# ESP32-S3 register map
Vendor: ESPRESSIF SYSTEMS (SHANGHAI) CO., LTD.; Series: ESP32 S-Series; File version: 22
CPU: Xtensa LX7 r0p0, little endian, no MPU, FPU, 0 interrupt priority bits
Address unit: 32 bits
Registers are 32-bit, read-write, reset 0x0 unless marked. A register's access mark holds for its fields unless they carry their own. Offsets are from the block's base; [hi:lo] are bit positions; {n}, {i} and the like mark numbered series.

## SENSITIVE (part 1 of 2) — SENSITIVE Peripheral
Base 0x600C1000
0x00 CACHE_DATAARRAY_CONNECT_0 — Cache data array configuration register 0.
  [0] CACHE_DATAARRAY_CONNECT_LOCK — Set 1 to lock cache data array registers.
0x04 CACHE_DATAARRAY_CONNECT_1 reset 0xFF — Cache data array configuration register 1.
  [7:0] CACHE_DATAARRAY_CONNECT_FLATTEN — Cache data array connection configuration.
0x08 APB_PERIPHERAL_ACCESS_0 — APB peripheral configuration register 0.
  [0] APB_PERIPHERAL_ACCESS_LOCK — Set 1 to lock APB peripheral Configuration Register.
0x0C APB_PERIPHERAL_ACCESS_1 reset 0x1 — APB peripheral configuration register 1.
  [0] APB_PERIPHERAL_ACCESS_SPLIT_BURST — Set 1 to support split function for AHB access to APB peripherals.
0x10 INTERNAL_SRAM_USAGE_0 — Internal SRAM configuration register 0.
  [0] INTERNAL_SRAM_USAGE_LOCK — Set 1 to lock internal SRAM Configuration Register.
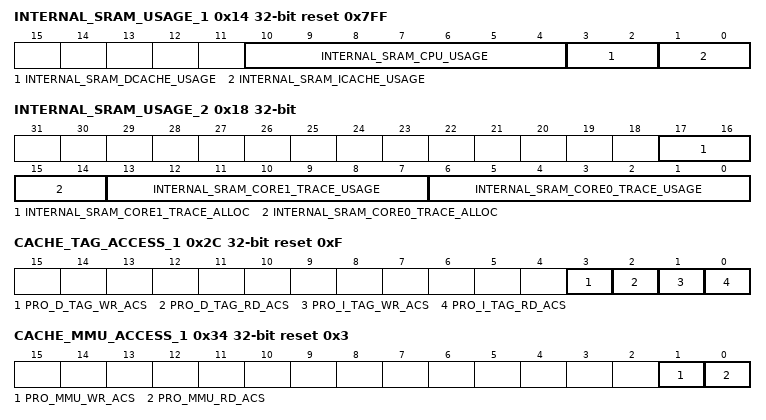
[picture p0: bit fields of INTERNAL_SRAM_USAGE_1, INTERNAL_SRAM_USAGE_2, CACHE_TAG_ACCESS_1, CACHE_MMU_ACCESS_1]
0x14 INTERNAL_SRAM_USAGE_1 reset 0x7FF — Internal SRAM configuration register 1.
  [10:4] INTERNAL_SRAM_CPU_USAGE — Set 1 to someone bit means corresponding internal SRAM level can be accessed by cpu.
  [3:2] INTERNAL_SRAM_DCACHE_USAGE — Set 1 to someone bit means corresponding internal SRAM level can be accessed by dcache.
  [1:0] INTERNAL_SRAM_ICACHE_USAGE — Set 1 to someone bit means corresponding internal SRAM level can be accessed by icache.
0x18 INTERNAL_SRAM_USAGE_2 — Internal SRAM configuration register 2.
  [17:16] INTERNAL_SRAM_CORE1_TRACE_ALLOC — Which internal SRAM bank (16KB) of 64KB can be accessed by core1 trace bus.
  [15:14] INTERNAL_SRAM_CORE0_TRACE_ALLOC — Which internal SRAM bank (16KB) of 64KB can be accessed by core0 trace bus.
  [13:7] INTERNAL_SRAM_CORE1_TRACE_USAGE — Set 1 to someone bit means corresponding internal SRAM level can be accessed by core1 trace bus.
  [6:0] INTERNAL_SRAM_CORE0_TRACE_USAGE — Set 1 to someone bit means corresponding internal SRAM level can be accessed by core0 trace bus.
0x1C INTERNAL_SRAM_USAGE_3 — Internal SRAM configuration register 3.
  [3:0] INTERNAL_SRAM_MAC_DUMP_USAGE — Set 1 to someone bit means corresponding internal SRAM level can be accessed by mac dump.
0x20 INTERNAL_SRAM_USAGE_4 — Internal SRAM configuration register 4.
  [6:0] INTERNAL_SRAM_LOG_USAGE — Set 1 to someone bit means corresponding internal SRAM level can be accessed by log bus.
0x24 RETENTION_DISABLE — Retention configuration register.
  [0] RETENTION_DISABLE — Set 1 to disable retention function and lock disable state.
0x28 CACHE_TAG_ACCESS_0 — Cache tag configuration register 0.
  [0] CACHE_TAG_ACCESS_LOCK — Set 1 to lock cache tag Configuration Register.
0x2C CACHE_TAG_ACCESS_1 reset 0xF — Cache tag configuration register 1.
  [3] PRO_D_TAG_WR_ACS — Set 1 to enable Dcache wrtie access tag memory.
  [2] PRO_D_TAG_RD_ACS — Set 1 to enable Dcache read access tag memory.
  [1] PRO_I_TAG_WR_ACS — Set 1 to enable Icache wrtie access tag memory.
  [0] PRO_I_TAG_RD_ACS — Set 1 to enable Icache read access tag memory.
0x30 CACHE_MMU_ACCESS_0 — Cache MMU configuration register 0.
  [0] CACHE_MMU_ACCESS_LOCK — Set 1 to lock cache MMU registers.
0x34 CACHE_MMU_ACCESS_1 reset 0x3 — Cache MMU configuration register 1.
  [1] PRO_MMU_WR_ACS — Set 1 to enable write access MMU memory.
  [0] PRO_MMU_RD_ACS — Set 1 to enable read access MMU memory.
0x38 DMA_APBPERI_SPI2_PMS_CONSTRAIN_0 — spi2 dma permission configuration register 0.
  [0] DMA_APBPERI_SPI2_PMS_CONSTRAIN_LOCK — Set 1 to lock spi2 dma permission Configuration Register.
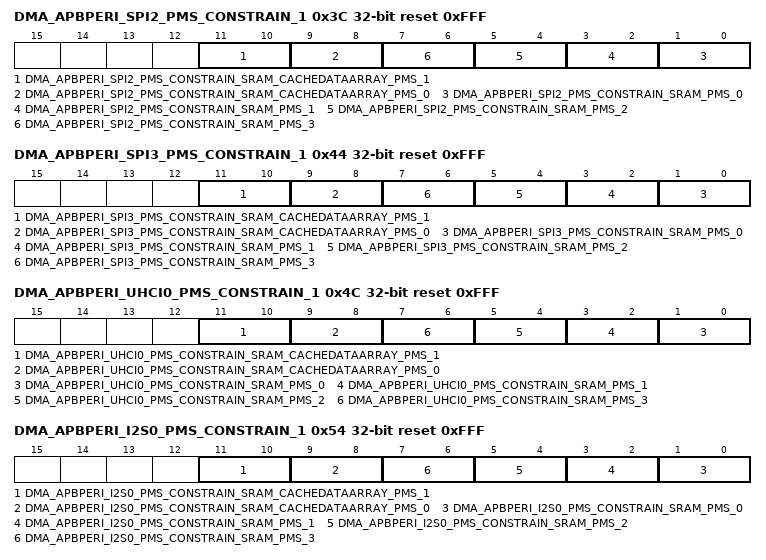
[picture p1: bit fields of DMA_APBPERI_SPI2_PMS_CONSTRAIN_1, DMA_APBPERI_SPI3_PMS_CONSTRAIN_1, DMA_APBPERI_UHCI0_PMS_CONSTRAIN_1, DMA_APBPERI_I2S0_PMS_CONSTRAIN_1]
0x3C DMA_APBPERI_SPI2_PMS_CONSTRAIN_1 reset 0xFFF — spi2 dma permission configuration register 1.
  [11:10] DMA_APBPERI_SPI2_PMS_CONSTRAIN_SRAM_CACHEDATAARRAY_PMS_1 — spi2's permission(store,load) in dcache data sram block1
  [9:8] DMA_APBPERI_SPI2_PMS_CONSTRAIN_SRAM_CACHEDATAARRAY_PMS_0 — spi2's permission(store,load) in dcache data sram block0
  [2n+1:2n] DMA_APBPERI_SPI2_PMS_CONSTRAIN_SRAM_PMS_{n} (n=0..3) — spi2's permission(store,load) in data region{n} of SRAM
0x40 DMA_APBPERI_SPI3_PMS_CONSTRAIN_0 — spi3 dma permission configuration register 0.
  [0] DMA_APBPERI_SPI3_PMS_CONSTRAIN_LOCK — Set 1 to lock spi3 dma permission Configuration Register.
0x44 DMA_APBPERI_SPI3_PMS_CONSTRAIN_1 reset 0xFFF — spi3 dma permission configuration register 1.
  [11:10] DMA_APBPERI_SPI3_PMS_CONSTRAIN_SRAM_CACHEDATAARRAY_PMS_1 — spi3's permission(store,load) in dcache data sram block1
  [9:8] DMA_APBPERI_SPI3_PMS_CONSTRAIN_SRAM_CACHEDATAARRAY_PMS_0 — spi3's permission(store,load) in dcache data sram block0
  [2n+1:2n] DMA_APBPERI_SPI3_PMS_CONSTRAIN_SRAM_PMS_{n} (n=0..3) — spi3's permission(store,load) in data region{n} of SRAM
0x48 DMA_APBPERI_UHCI0_PMS_CONSTRAIN_0 — uhci0 dma permission configuration register 0.
  [0] DMA_APBPERI_UHCI0_PMS_CONSTRAIN_LOCK — Set 1 to lock uhci0 dma permission Configuration Register.
0x4C DMA_APBPERI_UHCI0_PMS_CONSTRAIN_1 reset 0xFFF — uhci0 dma permission configuration register 1.
  [11:10] DMA_APBPERI_UHCI0_PMS_CONSTRAIN_SRAM_CACHEDATAARRAY_PMS_1 — uhci0's permission(store,load) in dcache data sram block1
  [9:8] DMA_APBPERI_UHCI0_PMS_CONSTRAIN_SRAM_CACHEDATAARRAY_PMS_0 — uhci0's permission(store,load) in dcache data sram block0
  [2n+1:2n] DMA_APBPERI_UHCI0_PMS_CONSTRAIN_SRAM_PMS_{n} (n=0..3) — uhci0's permission(store,load) in data region{n} of SRAM
0x50 DMA_APBPERI_I2S0_PMS_CONSTRAIN_0 — i2s0 dma permission configuration register 0.
  [0] DMA_APBPERI_I2S0_PMS_CONSTRAIN_LOCK — Set 1 to lock i2s0 dma permission Configuration Register.
0x54 DMA_APBPERI_I2S0_PMS_CONSTRAIN_1 reset 0xFFF — i2s0 dma permission configuration register 1.
  [11:10] DMA_APBPERI_I2S0_PMS_CONSTRAIN_SRAM_CACHEDATAARRAY_PMS_1 — i2s0's permission(store,load) in dcache data sram block1
  [9:8] DMA_APBPERI_I2S0_PMS_CONSTRAIN_SRAM_CACHEDATAARRAY_PMS_0 — i2s0's permission(store,load) in dcache data sram block0
  [2n+1:2n] DMA_APBPERI_I2S0_PMS_CONSTRAIN_SRAM_PMS_{n} (n=0..3) — i2s0's permission(store,load) in data region{n} of SRAM
0x58 DMA_APBPERI_I2S1_PMS_CONSTRAIN_0 — i2s1 dma permission configuration register 0.
  [0] DMA_APBPERI_I2S1_PMS_CONSTRAIN_LOCK — Set 1 to lock i2s1 dma permission Configuration Register.
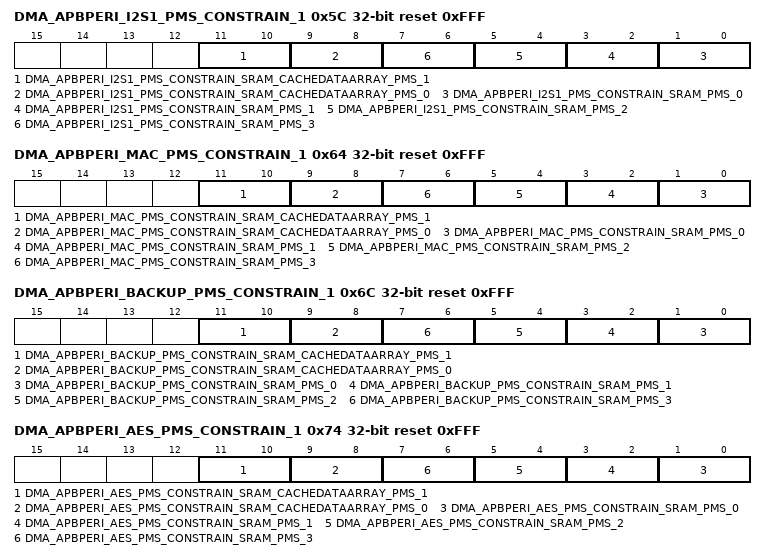
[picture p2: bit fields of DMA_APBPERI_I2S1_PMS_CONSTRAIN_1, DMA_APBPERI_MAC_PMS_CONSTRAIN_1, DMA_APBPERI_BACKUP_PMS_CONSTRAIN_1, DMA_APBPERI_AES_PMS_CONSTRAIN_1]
0x5C DMA_APBPERI_I2S1_PMS_CONSTRAIN_1 reset 0xFFF — i2s1 dma permission configuration register 1.
  [11:10] DMA_APBPERI_I2S1_PMS_CONSTRAIN_SRAM_CACHEDATAARRAY_PMS_1 — i2s1's permission(store,load) in dcache data sram block1
  [9:8] DMA_APBPERI_I2S1_PMS_CONSTRAIN_SRAM_CACHEDATAARRAY_PMS_0 — i2s1's permission(store,load) in dcache data sram block0
  [2n+1:2n] DMA_APBPERI_I2S1_PMS_CONSTRAIN_SRAM_PMS_{n} (n=0..3) — i2s1's permission(store,load) in data region{n} of SRAM
0x60 DMA_APBPERI_MAC_PMS_CONSTRAIN_0 — mac dma permission configuration register 0.
  [0] DMA_APBPERI_MAC_PMS_CONSTRAIN_LOCK — Set 1 to lock mac dma permission Configuration Register.
0x64 DMA_APBPERI_MAC_PMS_CONSTRAIN_1 reset 0xFFF — mac dma permission configuration register 1.
  [11:10] DMA_APBPERI_MAC_PMS_CONSTRAIN_SRAM_CACHEDATAARRAY_PMS_1 — mac's permission(store,load) in dcache data sram block1
  [9:8] DMA_APBPERI_MAC_PMS_CONSTRAIN_SRAM_CACHEDATAARRAY_PMS_0 — mac's permission(store,load) in dcache data sram block0
  [2n+1:2n] DMA_APBPERI_MAC_PMS_CONSTRAIN_SRAM_PMS_{n} (n=0..3) — mac's permission(store,load) in data region{n} of SRAM
0x68 DMA_APBPERI_BACKUP_PMS_CONSTRAIN_0 — backup dma permission configuration register 0.
  [0] DMA_APBPERI_BACKUP_PMS_CONSTRAIN_LOCK — Set 1 to lock backup dma permission Configuration Register.
0x6C DMA_APBPERI_BACKUP_PMS_CONSTRAIN_1 reset 0xFFF — backup dma permission configuration register 1.
  [11:10] DMA_APBPERI_BACKUP_PMS_CONSTRAIN_SRAM_CACHEDATAARRAY_PMS_1 — backup's permission(store,load) in dcache data sram block1
  [9:8] DMA_APBPERI_BACKUP_PMS_CONSTRAIN_SRAM_CACHEDATAARRAY_PMS_0 — backup's permission(store,load) in dcache data sram block0
  [2n+1:2n] DMA_APBPERI_BACKUP_PMS_CONSTRAIN_SRAM_PMS_{n} (n=0..3) — backup's permission(store,load) in data region{n} of SRAM
0x70 DMA_APBPERI_AES_PMS_CONSTRAIN_0 — aes dma permission configuration register 0.
  [0] DMA_APBPERI_AES_PMS_CONSTRAIN_LOCK — Set 1 to lock aes dma permission Configuration Register.
0x74 DMA_APBPERI_AES_PMS_CONSTRAIN_1 reset 0xFFF — aes dma permission configuration register 1.
  [11:10] DMA_APBPERI_AES_PMS_CONSTRAIN_SRAM_CACHEDATAARRAY_PMS_1 — aes's permission(store,load) in dcache data sram block1
  [9:8] DMA_APBPERI_AES_PMS_CONSTRAIN_SRAM_CACHEDATAARRAY_PMS_0 — aes's permission(store,load) in dcache data sram block0
  [2n+1:2n] DMA_APBPERI_AES_PMS_CONSTRAIN_SRAM_PMS_{n} (n=0..3) — aes's permission(store,load) in data region{n} of SRAM
0x78 DMA_APBPERI_SHA_PMS_CONSTRAIN_0 — sha dma permission configuration register 0.
  [0] DMA_APBPERI_SHA_PMS_CONSTRAIN_LOCK — Set 1 to lock sha dma permission Configuration Register.
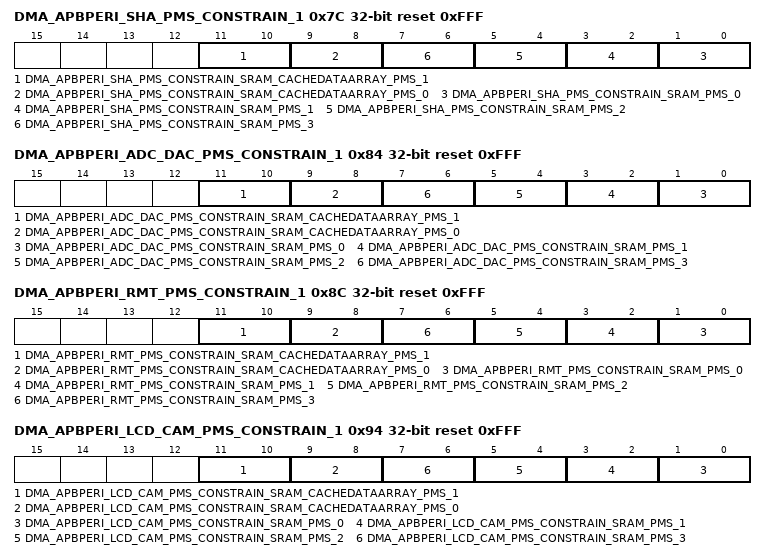
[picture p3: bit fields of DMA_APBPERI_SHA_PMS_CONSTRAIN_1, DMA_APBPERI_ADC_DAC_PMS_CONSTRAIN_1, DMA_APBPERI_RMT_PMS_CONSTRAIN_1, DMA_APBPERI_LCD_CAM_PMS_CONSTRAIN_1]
0x7C DMA_APBPERI_SHA_PMS_CONSTRAIN_1 reset 0xFFF — sha dma permission configuration register 1.
  [11:10] DMA_APBPERI_SHA_PMS_CONSTRAIN_SRAM_CACHEDATAARRAY_PMS_1 — sha's permission(store,load) in dcache data sram block1
  [9:8] DMA_APBPERI_SHA_PMS_CONSTRAIN_SRAM_CACHEDATAARRAY_PMS_0 — sha's permission(store,load) in dcache data sram block0
  [2n+1:2n] DMA_APBPERI_SHA_PMS_CONSTRAIN_SRAM_PMS_{n} (n=0..3) — sha's permission(store,load) in data region{n} of SRAM
0x80 DMA_APBPERI_ADC_DAC_PMS_CONSTRAIN_0 — adc_dac dma permission configuration register 0.
  [0] DMA_APBPERI_ADC_DAC_PMS_CONSTRAIN_LOCK — Set 1 to lock adc_dac dma permission Configuration Register.
0x84 DMA_APBPERI_ADC_DAC_PMS_CONSTRAIN_1 reset 0xFFF — adc_dac dma permission configuration register 1.
  [11:10] DMA_APBPERI_ADC_DAC_PMS_CONSTRAIN_SRAM_CACHEDATAARRAY_PMS_1 — adc_dac's permission(store,load) in dcache data sram block1
  [9:8] DMA_APBPERI_ADC_DAC_PMS_CONSTRAIN_SRAM_CACHEDATAARRAY_PMS_0 — adc_dac's permission(store,load) in dcache data sram block0
  [2n+1:2n] DMA_APBPERI_ADC_DAC_PMS_CONSTRAIN_SRAM_PMS_{n} (n=0..3) — adc_dac's permission(store,load) in data region{n} of SRAM
0x88 DMA_APBPERI_RMT_PMS_CONSTRAIN_0 — rmt dma permission configuration register 0.
  [0] DMA_APBPERI_RMT_PMS_CONSTRAIN_LOCK — Set 1 to lock rmt dma permission Configuration Register.
0x8C DMA_APBPERI_RMT_PMS_CONSTRAIN_1 reset 0xFFF — rmt dma permission configuration register 1.
  [11:10] DMA_APBPERI_RMT_PMS_CONSTRAIN_SRAM_CACHEDATAARRAY_PMS_1 — rmt's permission(store,load) in dcache data sram block1
  [9:8] DMA_APBPERI_RMT_PMS_CONSTRAIN_SRAM_CACHEDATAARRAY_PMS_0 — rmt's permission(store,load) in dcache data sram block0
  [2n+1:2n] DMA_APBPERI_RMT_PMS_CONSTRAIN_SRAM_PMS_{n} (n=0..3) — rmt's permission(store,load) in data region{n} of SRAM
0x90 DMA_APBPERI_LCD_CAM_PMS_CONSTRAIN_0 — lcd_cam dma permission configuration register 0.
  [0] DMA_APBPERI_LCD_CAM_PMS_CONSTRAIN_LOCK — Set 1 to lock lcd_cam dma permission Configuration Register.
0x94 DMA_APBPERI_LCD_CAM_PMS_CONSTRAIN_1 reset 0xFFF — lcd_cam dma permission configuration register 1.
  [11:10] DMA_APBPERI_LCD_CAM_PMS_CONSTRAIN_SRAM_CACHEDATAARRAY_PMS_1 — lcd_cam's permission(store,load) in dcache data sram block1
  [9:8] DMA_APBPERI_LCD_CAM_PMS_CONSTRAIN_SRAM_CACHEDATAARRAY_PMS_0 — lcd_cam's permission(store,load) in dcache data sram block0
  [2n+1:2n] DMA_APBPERI_LCD_CAM_PMS_CONSTRAIN_SRAM_PMS_{n} (n=0..3) — lcd_cam's permission(store,load) in data region{n} of SRAM
0x98 DMA_APBPERI_USB_PMS_CONSTRAIN_0 — usb dma permission configuration register 0.
  [0] DMA_APBPERI_USB_PMS_CONSTRAIN_LOCK — Set 1 to lock usb dma permission Configuration Register.
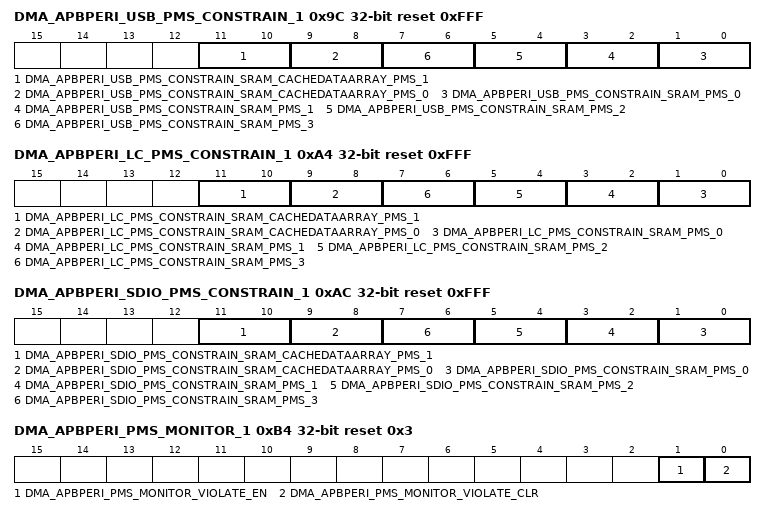
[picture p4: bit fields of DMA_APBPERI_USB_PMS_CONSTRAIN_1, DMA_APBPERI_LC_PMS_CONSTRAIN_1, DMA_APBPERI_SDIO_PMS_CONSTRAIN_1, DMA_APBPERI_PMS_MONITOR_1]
0x9C DMA_APBPERI_USB_PMS_CONSTRAIN_1 reset 0xFFF — usb dma permission configuration register 1.
  [11:10] DMA_APBPERI_USB_PMS_CONSTRAIN_SRAM_CACHEDATAARRAY_PMS_1 — usb's permission(store,load) in dcache data sram block1
  [9:8] DMA_APBPERI_USB_PMS_CONSTRAIN_SRAM_CACHEDATAARRAY_PMS_0 — usb's permission(store,load) in dcache data sram block0
  [2n+1:2n] DMA_APBPERI_USB_PMS_CONSTRAIN_SRAM_PMS_{n} (n=0..3) — usb's permission(store,load) in data region{n} of SRAM
0xA0 DMA_APBPERI_LC_PMS_CONSTRAIN_0 — lc dma permission configuration register 0.
  [0] DMA_APBPERI_LC_PMS_CONSTRAIN_LOCK — Set 1 to lock lc dma permission Configuration Register.
0xA4 DMA_APBPERI_LC_PMS_CONSTRAIN_1 reset 0xFFF — lc dma permission configuration register 1.
  [11:10] DMA_APBPERI_LC_PMS_CONSTRAIN_SRAM_CACHEDATAARRAY_PMS_1 — lc's permission(store,load) in dcache data sram block1
  [9:8] DMA_APBPERI_LC_PMS_CONSTRAIN_SRAM_CACHEDATAARRAY_PMS_0 — lc's permission(store,load) in dcache data sram block0
  [2n+1:2n] DMA_APBPERI_LC_PMS_CONSTRAIN_SRAM_PMS_{n} (n=0..3) — lc's permission(store,load) in data region{n} of SRAM
0xA8 DMA_APBPERI_SDIO_PMS_CONSTRAIN_0 — sdio dma permission configuration register 0.
  [0] DMA_APBPERI_SDIO_PMS_CONSTRAIN_LOCK — Set 1 to lock sdio dma permission Configuration Register.
0xAC DMA_APBPERI_SDIO_PMS_CONSTRAIN_1 reset 0xFFF — sdio dma permission configuration register 1.
  [11:10] DMA_APBPERI_SDIO_PMS_CONSTRAIN_SRAM_CACHEDATAARRAY_PMS_1 — sdio's permission(store,load) in dcache data sram block1
  [9:8] DMA_APBPERI_SDIO_PMS_CONSTRAIN_SRAM_CACHEDATAARRAY_PMS_0 — sdio's permission(store,load) in dcache data sram block0
  [2n+1:2n] DMA_APBPERI_SDIO_PMS_CONSTRAIN_SRAM_PMS_{n} (n=0..3) — sdio's permission(store,load) in data region{n} of SRAM
0xB0 DMA_APBPERI_PMS_MONITOR_0 — dma permission monitor configuration register 0.
  [0] DMA_APBPERI_PMS_MONITOR_LOCK — Set 1 to lock dma permission monitor Configuration Register.
0xB4 DMA_APBPERI_PMS_MONITOR_1 reset 0x3 — dma permission monitor configuration register 1.
  [1] DMA_APBPERI_PMS_MONITOR_VIOLATE_EN — Set 1 to enable dma pms monitor, if dma access violated permission, will trigger interrupt.
  [0] DMA_APBPERI_PMS_MONITOR_VIOLATE_CLR — Set 1 to clear dma_pms_monitor_violate interrupt
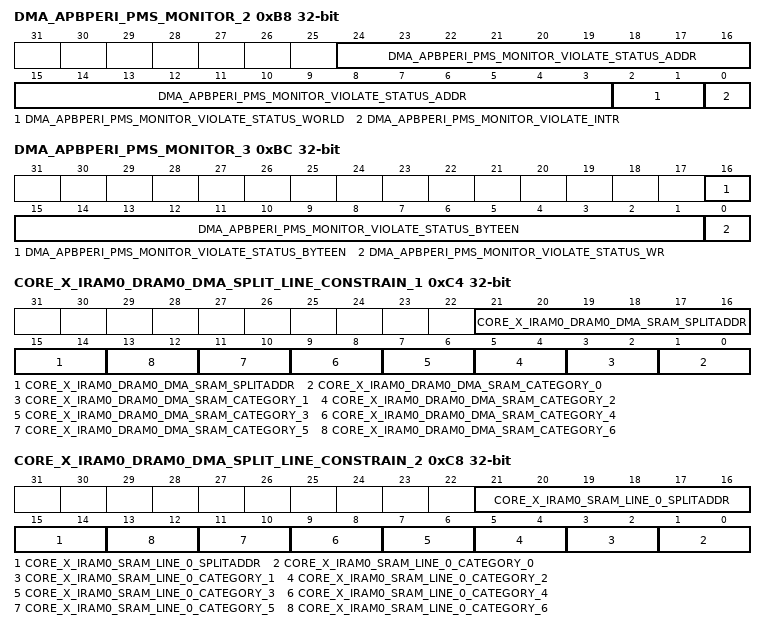
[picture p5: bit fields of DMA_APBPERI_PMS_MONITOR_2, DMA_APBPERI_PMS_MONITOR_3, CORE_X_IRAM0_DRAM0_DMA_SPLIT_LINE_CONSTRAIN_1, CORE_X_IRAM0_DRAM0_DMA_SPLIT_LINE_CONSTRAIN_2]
0xB8 DMA_APBPERI_PMS_MONITOR_2 ro — dma permission monitor configuration register 2.
  [24:3] DMA_APBPERI_PMS_MONITOR_VIOLATE_STATUS_ADDR — recorded dma's address bit[25:4] status when dma access violated permission, real address is 0x3c00_0000+addr*16
  [2:1] DMA_APBPERI_PMS_MONITOR_VIOLATE_STATUS_WORLD — recorded dma's world status when dma access violated permission
  [0] DMA_APBPERI_PMS_MONITOR_VIOLATE_INTR — recorded dma's interrupt status when dma access violated permission
0xBC DMA_APBPERI_PMS_MONITOR_3 ro — dma permission monitor configuration register 3.
  [16:1] DMA_APBPERI_PMS_MONITOR_VIOLATE_STATUS_BYTEEN — recorded dma's byte enable status when dma access violated permission
  [0] DMA_APBPERI_PMS_MONITOR_VIOLATE_STATUS_WR — recorded dma's write status when dma access violated permission, 1(write), 0(read)
0xC0 CORE_X_IRAM0_DRAM0_DMA_SPLIT_LINE_CONSTRAIN_0 — sram split line configuration register 0
  [0] CORE_X_IRAM0_DRAM0_DMA_SPLIT_LINE_CONSTRAIN_LOCK — Set 1 to lock sram split configuration register
0xC4 CORE_X_IRAM0_DRAM0_DMA_SPLIT_LINE_CONSTRAIN_1 — sram split line configuration register 1
  [21:14] CORE_X_IRAM0_DRAM0_DMA_SRAM_SPLITADDR — splitaddr of core_x_iram0_dram_dma_line, configured as [15:8]bit of actual address
  [2n+1:2n] CORE_X_IRAM0_DRAM0_DMA_SRAM_CATEGORY_{n} (n=0..6) — category{n} of core_x_iram0_dram_dma_line, if the splitaddress in block{n} of SRAM, configured as 0x10, else if the splitaddress below block{n} of SRAM, configured as 0x11, else if splitaddress higher than block{n} of SRAM, configured as 0x00
0xC8 CORE_X_IRAM0_DRAM0_DMA_SPLIT_LINE_CONSTRAIN_2 — sram split line configuration register 1
  [21:14] CORE_X_IRAM0_SRAM_LINE_0_SPLITADDR — splitaddr of core_x_iram0_dram_dma_line, configured as [15:8]bit of actual address
  [2n+1:2n] CORE_X_IRAM0_SRAM_LINE_0_CATEGORY_{n} (n=0..6) — category{n} of core_x_iram0_dram_dma_line, if the splitaddress in block{n} of SRAM, configured as 0x10, else if the splitaddress below block{n} of SRAM, configured as 0x11, else if splitaddress higher than block{n} of SRAM, configured as 0x00
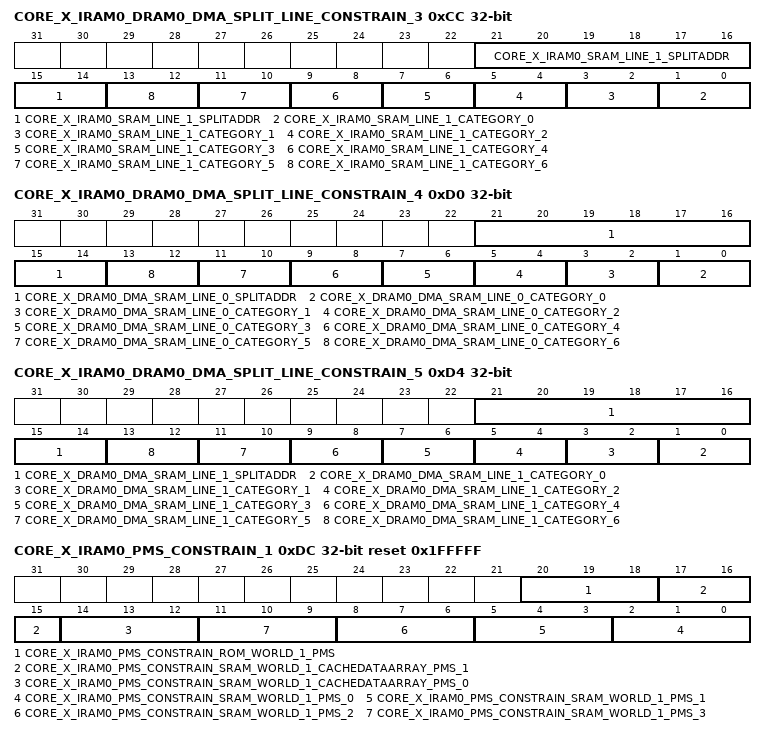
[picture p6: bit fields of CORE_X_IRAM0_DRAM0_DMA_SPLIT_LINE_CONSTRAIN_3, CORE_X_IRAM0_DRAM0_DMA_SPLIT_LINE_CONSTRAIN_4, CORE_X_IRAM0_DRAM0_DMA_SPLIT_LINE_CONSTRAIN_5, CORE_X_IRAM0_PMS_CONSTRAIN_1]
0xCC CORE_X_IRAM0_DRAM0_DMA_SPLIT_LINE_CONSTRAIN_3 — sram split line configuration register 1
  [21:14] CORE_X_IRAM0_SRAM_LINE_1_SPLITADDR — splitaddr of core_x_iram0_dram_dma_line, configured as [15:8]bit of actual address
  [2n+1:2n] CORE_X_IRAM0_SRAM_LINE_1_CATEGORY_{n} (n=0..6) — category{n} of core_x_iram0_dram_dma_line, if the splitaddress in block{n} of SRAM, configured as 0x10, else if the splitaddress below block{n} of SRAM, configured as 0x11, else if splitaddress higher than block{n} of SRAM, configured as 0x00
0xD0 CORE_X_IRAM0_DRAM0_DMA_SPLIT_LINE_CONSTRAIN_4 — sram split line configuration register 1
  [21:14] CORE_X_DRAM0_DMA_SRAM_LINE_0_SPLITADDR — splitaddr of core_x_iram0_dram_dma_line, configured as [15:8]bit of actual address
  [2n+1:2n] CORE_X_DRAM0_DMA_SRAM_LINE_0_CATEGORY_{n} (n=0..6) — category{n} of core_x_iram0_dram_dma_line, if the splitaddress in block{n} of SRAM, configured as 0x10, else if the splitaddress below block{n} of SRAM, configured as 0x11, else if splitaddress higher than block{n} of SRAM, configured as 0x00
0xD4 CORE_X_IRAM0_DRAM0_DMA_SPLIT_LINE_CONSTRAIN_5 — sram split line configuration register 1
  [21:14] CORE_X_DRAM0_DMA_SRAM_LINE_1_SPLITADDR — splitaddr of core_x_iram0_dram_dma_line, configured as [15:8]bit of actual address
  [2n+1:2n] CORE_X_DRAM0_DMA_SRAM_LINE_1_CATEGORY_{n} (n=0..6) — category{n} of core_x_iram0_dram_dma_line, if the splitaddress in block{n} of SRAM, configured as 0x10, else if the splitaddress below block{n} of SRAM, configured as 0x11, else if splitaddress higher than block{n} of SRAM, configured as 0x00
0xD8 CORE_X_IRAM0_PMS_CONSTRAIN_0 — corex iram0 permission configuration register 0
  [0] CORE_X_IRAM0_PMS_CONSTRAIN_LOCK — Set 1 to lock corex iram0 permission configuration register
0xDC CORE_X_IRAM0_PMS_CONSTRAIN_1 reset 0x1FFFFF — corex iram0 permission configuration register 0
  [20:18] CORE_X_IRAM0_PMS_CONSTRAIN_ROM_WORLD_1_PMS — core0/core1's permission of rom in world1
  [17:15] CORE_X_IRAM0_PMS_CONSTRAIN_SRAM_WORLD_1_CACHEDATAARRAY_PMS_1 — core0/core1's permission of icache data sram block1 in world1
  [14:12] CORE_X_IRAM0_PMS_CONSTRAIN_SRAM_WORLD_1_CACHEDATAARRAY_PMS_0 — core0/core1's permission of icache data sram block0 in world1
  [3n+2:3n] CORE_X_IRAM0_PMS_CONSTRAIN_SRAM_WORLD_1_PMS_{n} (n=0..3) — core0/core1's permission of instruction region{n} of SRAM in world1
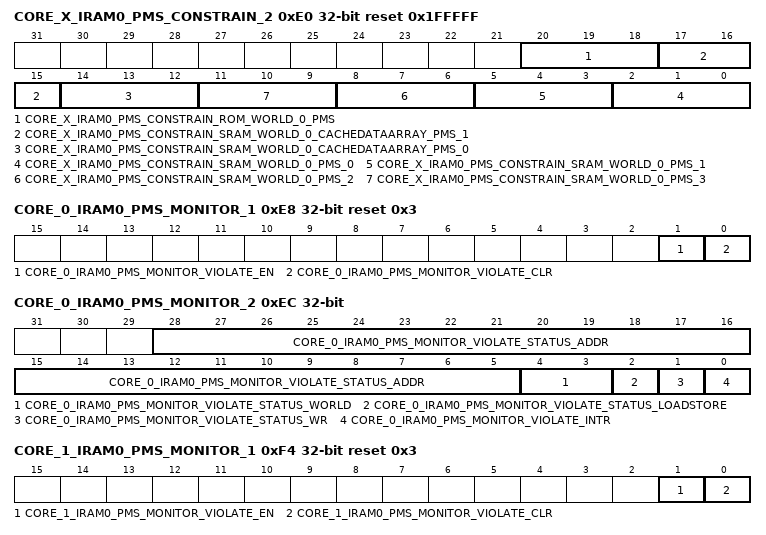
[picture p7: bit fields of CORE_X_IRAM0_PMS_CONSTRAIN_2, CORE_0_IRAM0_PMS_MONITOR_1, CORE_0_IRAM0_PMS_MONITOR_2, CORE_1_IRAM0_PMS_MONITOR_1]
0xE0 CORE_X_IRAM0_PMS_CONSTRAIN_2 reset 0x1FFFFF — corex iram0 permission configuration register 1
  [20:18] CORE_X_IRAM0_PMS_CONSTRAIN_ROM_WORLD_0_PMS — core0/core1's permission of rom in world1
  [17:15] CORE_X_IRAM0_PMS_CONSTRAIN_SRAM_WORLD_0_CACHEDATAARRAY_PMS_1 — core0/core1's permission of icache data sram block1 in world1
  [14:12] CORE_X_IRAM0_PMS_CONSTRAIN_SRAM_WORLD_0_CACHEDATAARRAY_PMS_0 — core0/core1's permission of icache data sram block0 in world1
  [3n+2:3n] CORE_X_IRAM0_PMS_CONSTRAIN_SRAM_WORLD_0_PMS_{n} (n=0..3) — core0/core1's permission of instruction region{n} of SRAM in world1
0xE4 CORE_0_IRAM0_PMS_MONITOR_0 — core0 iram0 permission monitor configuration register 0
  [0] CORE_0_IRAM0_PMS_MONITOR_LOCK — Set 1 to lock core0 iram0 permission monitor register
0xE8 CORE_0_IRAM0_PMS_MONITOR_1 reset 0x3 — core0 iram0 permission monitor configuration register 1
  [1] CORE_0_IRAM0_PMS_MONITOR_VIOLATE_EN — Set 1 to enable core0 iram0 permission monitor, when core0_iram violated permission, will trigger interrupt
  [0] CORE_0_IRAM0_PMS_MONITOR_VIOLATE_CLR — Set 1 to clear core0 iram0 permission violated interrupt
0xEC CORE_0_IRAM0_PMS_MONITOR_2 ro — core0 iram0 permission monitor configuration register 2
  [28:5] CORE_0_IRAM0_PMS_MONITOR_VIOLATE_STATUS_ADDR — recorded core0 iram0 address [25:2] status when core0 iram0 violated permission, the real address is 0x40000000+addr*4
  [4:3] CORE_0_IRAM0_PMS_MONITOR_VIOLATE_STATUS_WORLD — recorded core0 iram0 world status, 0x01 means world0, 0x10 means world1.
  [2] CORE_0_IRAM0_PMS_MONITOR_VIOLATE_STATUS_LOADSTORE — recorded core0 iram0 loadstore status, indicated the type of operation, 0(fetch), 1(load/store).
  [1] CORE_0_IRAM0_PMS_MONITOR_VIOLATE_STATUS_WR — recorded core0 iram0 wr status, only if loadstore is 1 have meaning, 1(store), 0(load).
  [0] CORE_0_IRAM0_PMS_MONITOR_VIOLATE_INTR — recorded core0 iram0 pms monitor interrupt status.
0xF0 CORE_1_IRAM0_PMS_MONITOR_0 — core1 iram0 permission monitor configuration register 0
  [0] CORE_1_IRAM0_PMS_MONITOR_LOCK — Set 1 to lock core1 iram0 permission monitor register
0xF4 CORE_1_IRAM0_PMS_MONITOR_1 reset 0x3 — core1 iram0 permission monitor configuration register 1
  [1] CORE_1_IRAM0_PMS_MONITOR_VIOLATE_EN — Set 1 to enable core1 iram0 permission monitor, when core1_iram violated permission, will trigger interrupt
  [0] CORE_1_IRAM0_PMS_MONITOR_VIOLATE_CLR — Set 1 to clear core1 iram0 permission violated interrupt
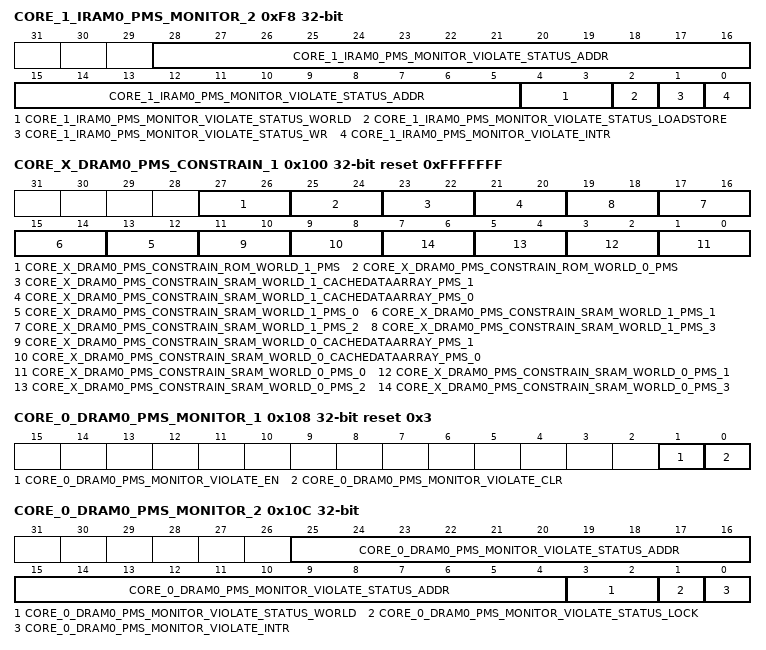
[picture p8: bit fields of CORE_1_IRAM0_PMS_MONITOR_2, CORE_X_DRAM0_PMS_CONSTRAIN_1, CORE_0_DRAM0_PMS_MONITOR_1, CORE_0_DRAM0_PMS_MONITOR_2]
0xF8 CORE_1_IRAM0_PMS_MONITOR_2 ro — core1 iram0 permission monitor configuration register 2
  [28:5] CORE_1_IRAM0_PMS_MONITOR_VIOLATE_STATUS_ADDR — recorded core1 iram0 address [25:2] status when core1 iram0 violated permission, the real address is 0x40000000+addr*4
  [4:3] CORE_1_IRAM0_PMS_MONITOR_VIOLATE_STATUS_WORLD — recorded core1 iram0 world status, 0x01 means world0, 0x10 means world1.
  [2] CORE_1_IRAM0_PMS_MONITOR_VIOLATE_STATUS_LOADSTORE — recorded core1 iram0 loadstore status, indicated the type of operation, 0(fetch), 1(load/store).
  [1] CORE_1_IRAM0_PMS_MONITOR_VIOLATE_STATUS_WR — recorded core1 iram0 wr status, only if loadstore is 1 have meaning, 1(store), 0(load).
  [0] CORE_1_IRAM0_PMS_MONITOR_VIOLATE_INTR — recorded core1 iram0 pms monitor interrupt status.
0xFC CORE_X_DRAM0_PMS_CONSTRAIN_0 — corex dram0 permission configuration register 0
  [0] CORE_X_DRAM0_PMS_CONSTRAIN_LOCK — Set 1 to lock corex dram0 permission configuration register
0x100 CORE_X_DRAM0_PMS_CONSTRAIN_1 reset 0xFFFFFFF — corex dram0 permission configuration register 1
  [27:26] CORE_X_DRAM0_PMS_CONSTRAIN_ROM_WORLD_1_PMS — core0/core1's permission(sotre,load) of rom in world1.
  [25:24] CORE_X_DRAM0_PMS_CONSTRAIN_ROM_WORLD_0_PMS — core0/core1's permission(sotre,load) of rom in world0.
  [23:22] CORE_X_DRAM0_PMS_CONSTRAIN_SRAM_WORLD_1_CACHEDATAARRAY_PMS_1 — core0/core1's permission of dcache data sram block1 in world1.
  [21:20] CORE_X_DRAM0_PMS_CONSTRAIN_SRAM_WORLD_1_CACHEDATAARRAY_PMS_0 — core0/core1's permission of dcache data sram block0 in world1.
  [2n+13:2n+12] CORE_X_DRAM0_PMS_CONSTRAIN_SRAM_WORLD_1_PMS_{n} (n=0..3) — core0/core1's permission of data region{n} of SRAM in world1.
  [11:10] CORE_X_DRAM0_PMS_CONSTRAIN_SRAM_WORLD_0_CACHEDATAARRAY_PMS_1 — core0/core1's permission of dcache data sram block1 in world0.
  [9:8] CORE_X_DRAM0_PMS_CONSTRAIN_SRAM_WORLD_0_CACHEDATAARRAY_PMS_0 — core0/core1's permission of dcache data sram block0 in world0.
  [2n+1:2n] CORE_X_DRAM0_PMS_CONSTRAIN_SRAM_WORLD_0_PMS_{n} (n=0..3) — core0/core1's permission of data region{n} of SRAM in world0.
0x104 CORE_0_DRAM0_PMS_MONITOR_0 — core0 dram0 permission monitor configuration register 0
  [0] CORE_0_DRAM0_PMS_MONITOR_LOCK — Set 1 to lock core0 dram0 permission monitor configuration register.
0x108 CORE_0_DRAM0_PMS_MONITOR_1 reset 0x3 — core0 dram0 permission monitor configuration register 1
  [1] CORE_0_DRAM0_PMS_MONITOR_VIOLATE_EN — Set 1 to enable core0 dram0 permission monitor interrupt.
  [0] CORE_0_DRAM0_PMS_MONITOR_VIOLATE_CLR — Set 1 to clear core0 dram0 permission monior interrupt.
0x10C CORE_0_DRAM0_PMS_MONITOR_2 ro — core0 dram0 permission monitor configuration register 2.
  [25:4] CORE_0_DRAM0_PMS_MONITOR_VIOLATE_STATUS_ADDR — recorded core0 dram0 address[25:4] status when core0 dram0 violated permission,the real address is 0x3c000000+addr*16
  [3:2] CORE_0_DRAM0_PMS_MONITOR_VIOLATE_STATUS_WORLD — recorded core0 dram0 world status, 0x1 means world0, 0x2 means world1.
  [1] CORE_0_DRAM0_PMS_MONITOR_VIOLATE_STATUS_LOCK — recorded core0 dram0 lock status, 1 means s32c1i access.
  [0] CORE_0_DRAM0_PMS_MONITOR_VIOLATE_INTR — recorded core0 dram0 permission monitor interrupt status.
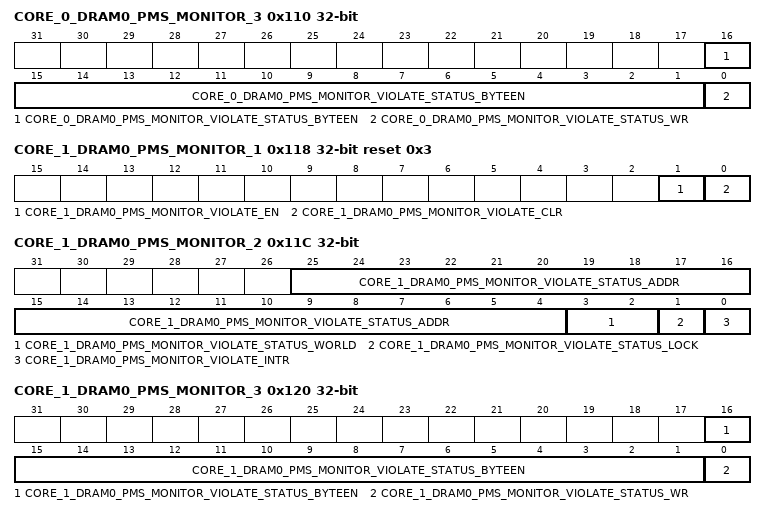
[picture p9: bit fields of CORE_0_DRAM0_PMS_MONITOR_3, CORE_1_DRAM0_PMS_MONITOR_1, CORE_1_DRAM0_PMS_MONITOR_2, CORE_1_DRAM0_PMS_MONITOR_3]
0x110 CORE_0_DRAM0_PMS_MONITOR_3 ro — core0 dram0 permission monitor configuration register 3.
  [16:1] CORE_0_DRAM0_PMS_MONITOR_VIOLATE_STATUS_BYTEEN — recorded core0 dram0 byteen status.
  [0] CORE_0_DRAM0_PMS_MONITOR_VIOLATE_STATUS_WR — recorded core0 dram0 wr status, 1 means store, 0 means load.
0x114 CORE_1_DRAM0_PMS_MONITOR_0 — core1 dram0 permission monitor configuration register 0
  [0] CORE_1_DRAM0_PMS_MONITOR_LOCK — Set 1 to lock core1 dram0 permission monitor configuration register.
0x118 CORE_1_DRAM0_PMS_MONITOR_1 reset 0x3 — core1 dram0 permission monitor configuration register 1
  [1] CORE_1_DRAM0_PMS_MONITOR_VIOLATE_EN — Set 1 to enable core1 dram0 permission monitor interrupt.
  [0] CORE_1_DRAM0_PMS_MONITOR_VIOLATE_CLR — Set 1 to clear core1 dram0 permission monior interrupt.
0x11C CORE_1_DRAM0_PMS_MONITOR_2 ro — core1 dram0 permission monitor configuration register 2.
  [25:4] CORE_1_DRAM0_PMS_MONITOR_VIOLATE_STATUS_ADDR — recorded core1 dram0 address[25:4] status when core1 dram0 violated permission,the real address is 0x3c000000+addr*16
  [3:2] CORE_1_DRAM0_PMS_MONITOR_VIOLATE_STATUS_WORLD — recorded core1 dram0 world status, 0x1 means world0, 0x2 means world1.
  [1] CORE_1_DRAM0_PMS_MONITOR_VIOLATE_STATUS_LOCK — recorded core1 dram0 lock status, 1 means s32c1i access.
  [0] CORE_1_DRAM0_PMS_MONITOR_VIOLATE_INTR — recorded core1 dram0 permission monitor interrupt status.
0x120 CORE_1_DRAM0_PMS_MONITOR_3 ro — core1 dram0 permission monitor configuration register 3.
  [16:1] CORE_1_DRAM0_PMS_MONITOR_VIOLATE_STATUS_BYTEEN — recorded core1 dram0 byteen status.
  [0] CORE_1_DRAM0_PMS_MONITOR_VIOLATE_STATUS_WR — recorded core1 dram0 wr status, 1 means store, 0 means load.
0x124 CORE_0_PIF_PMS_CONSTRAIN_0 — Core0 access peripherals permission configuration register 0.
  [0] CORE_0_PIF_PMS_CONSTRAIN_LOCK — Set 1 to lock core0 access peripherals permission Configuration Register.
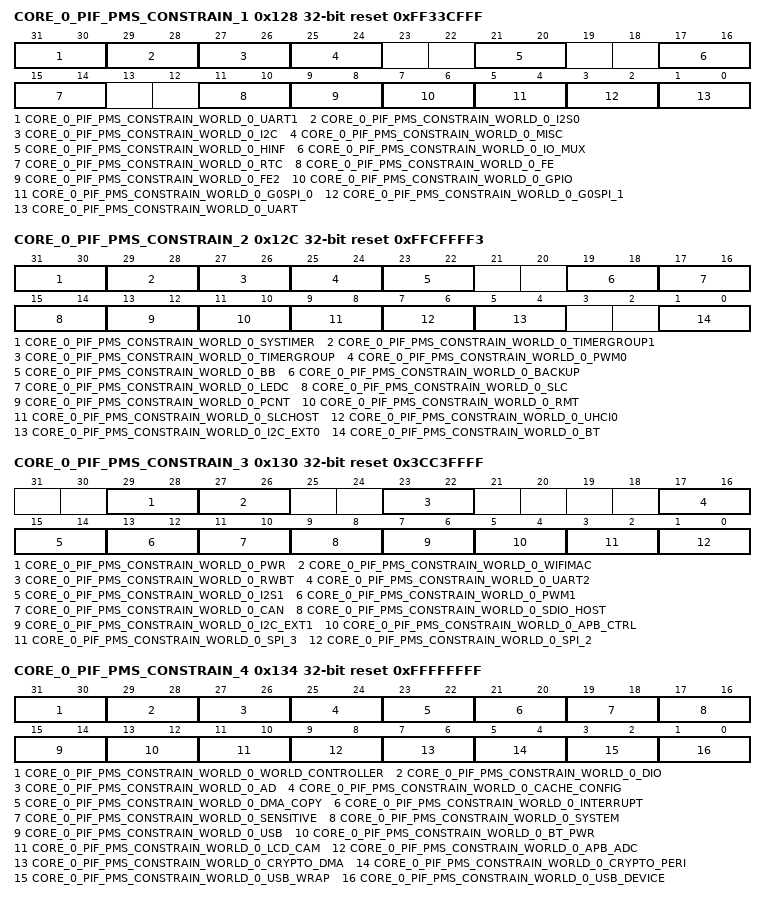
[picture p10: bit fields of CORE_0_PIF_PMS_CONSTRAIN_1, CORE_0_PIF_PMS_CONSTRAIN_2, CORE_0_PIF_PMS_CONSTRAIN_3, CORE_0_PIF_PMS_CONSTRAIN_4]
0x128 CORE_0_PIF_PMS_CONSTRAIN_1 reset 0xFF33CFFF — Core0 access peripherals permission configuration register 1.
  [31:30] CORE_0_PIF_PMS_CONSTRAIN_WORLD_0_UART1 — Core0 access uart1 permission in world0.
  [29:28] CORE_0_PIF_PMS_CONSTRAIN_WORLD_0_I2S0 — Core0 access i2s0 permission in world0.
  [27:26] CORE_0_PIF_PMS_CONSTRAIN_WORLD_0_I2C — Core0 access i2c permission in world0.
  [25:24] CORE_0_PIF_PMS_CONSTRAIN_WORLD_0_MISC — Core0 access misc permission in world0.
  [21:20] CORE_0_PIF_PMS_CONSTRAIN_WORLD_0_HINF — Core0 access hinf permission in world0.
  [17:16] CORE_0_PIF_PMS_CONSTRAIN_WORLD_0_IO_MUX — Core0 access io_mux permission in world0.
  [15:14] CORE_0_PIF_PMS_CONSTRAIN_WORLD_0_RTC — Core0 access rtc permission in world0.
  [11:10] CORE_0_PIF_PMS_CONSTRAIN_WORLD_0_FE — Core0 access fe permission in world0.
  [9:8] CORE_0_PIF_PMS_CONSTRAIN_WORLD_0_FE2 — Core0 access fe2 permission in world0.
  [7:6] CORE_0_PIF_PMS_CONSTRAIN_WORLD_0_GPIO — Core0 access gpio permission in world0.
  [5:4] CORE_0_PIF_PMS_CONSTRAIN_WORLD_0_G0SPI_0 — Core0 access g0spi_0 permission in world0.
  [3:2] CORE_0_PIF_PMS_CONSTRAIN_WORLD_0_G0SPI_1 — Core0 access g0spi_1 permission in world0.
  [1:0] CORE_0_PIF_PMS_CONSTRAIN_WORLD_0_UART — Core0 access uart permission in world0.
0x12C CORE_0_PIF_PMS_CONSTRAIN_2 reset 0xFFCFFFF3 — Core0 access peripherals permission configuration register 2.
  [31:30] CORE_0_PIF_PMS_CONSTRAIN_WORLD_0_SYSTIMER — Core0 access systimer permission in world0.
  [29:28] CORE_0_PIF_PMS_CONSTRAIN_WORLD_0_TIMERGROUP1 — Core0 access timergroup1 permission in world0.
  [27:26] CORE_0_PIF_PMS_CONSTRAIN_WORLD_0_TIMERGROUP — Core0 access timergroup permission in world0.
  [25:24] CORE_0_PIF_PMS_CONSTRAIN_WORLD_0_PWM0 — Core0 access pwm0 permission in world0.
  [23:22] CORE_0_PIF_PMS_CONSTRAIN_WORLD_0_BB — Core0 access bb permission in world0.
  [19:18] CORE_0_PIF_PMS_CONSTRAIN_WORLD_0_BACKUP — Core0 access backup permission in world0.
  [17:16] CORE_0_PIF_PMS_CONSTRAIN_WORLD_0_LEDC — Core0 access ledc permission in world0.
  [15:14] CORE_0_PIF_PMS_CONSTRAIN_WORLD_0_SLC — Core0 access slc permission in world0.
  [13:12] CORE_0_PIF_PMS_CONSTRAIN_WORLD_0_PCNT — Core0 access pcnt permission in world0.
  [11:10] CORE_0_PIF_PMS_CONSTRAIN_WORLD_0_RMT — Core0 access rmt permission in world0.
  [9:8] CORE_0_PIF_PMS_CONSTRAIN_WORLD_0_SLCHOST — Core0 access slchost permission in world0.
  [7:6] CORE_0_PIF_PMS_CONSTRAIN_WORLD_0_UHCI0 — Core0 access uhci0 permission in world0.
  [5:4] CORE_0_PIF_PMS_CONSTRAIN_WORLD_0_I2C_EXT0 — Core0 access i2c_ext0 permission in world0.
  [1:0] CORE_0_PIF_PMS_CONSTRAIN_WORLD_0_BT — Core0 access bt permission in world0.
0x130 CORE_0_PIF_PMS_CONSTRAIN_3 reset 0x3CC3FFFF — Core0 access peripherals permission configuration register 3.
  [29:28] CORE_0_PIF_PMS_CONSTRAIN_WORLD_0_PWR — Core0 access pwr permission in world0.
  [27:26] CORE_0_PIF_PMS_CONSTRAIN_WORLD_0_WIFIMAC — Core0 access wifimac permission in world0.
  [23:22] CORE_0_PIF_PMS_CONSTRAIN_WORLD_0_RWBT — Core0 access rwbt permission in world0.
  [17:16] CORE_0_PIF_PMS_CONSTRAIN_WORLD_0_UART2 — Core0 access uart2 permission in world0.
  [15:14] CORE_0_PIF_PMS_CONSTRAIN_WORLD_0_I2S1 — Core0 access i2s1 permission in world0.
  [13:12] CORE_0_PIF_PMS_CONSTRAIN_WORLD_0_PWM1 — Core0 access pwm1 permission in world0.
  [11:10] CORE_0_PIF_PMS_CONSTRAIN_WORLD_0_CAN — Core0 access can permission in world0.
  [9:8] CORE_0_PIF_PMS_CONSTRAIN_WORLD_0_SDIO_HOST — Core0 access sdio_host permission in world0.
  [7:6] CORE_0_PIF_PMS_CONSTRAIN_WORLD_0_I2C_EXT1 — Core0 access i2c_ext1 permission in world0.
  [5:4] CORE_0_PIF_PMS_CONSTRAIN_WORLD_0_APB_CTRL — Core0 access apb_ctrl permission in world0.
  [3:2] CORE_0_PIF_PMS_CONSTRAIN_WORLD_0_SPI_3 — Core0 access spi_3 permission in world0.
  [1:0] CORE_0_PIF_PMS_CONSTRAIN_WORLD_0_SPI_2 — Core0 access spi_2 permission in world0.
0x134 CORE_0_PIF_PMS_CONSTRAIN_4 reset 0xFFFFFFFF — Core0 access peripherals permission configuration register 4.
  [31:30] CORE_0_PIF_PMS_CONSTRAIN_WORLD_0_WORLD_CONTROLLER — Core0 access world_controller permission in world0.
  [29:28] CORE_0_PIF_PMS_CONSTRAIN_WORLD_0_DIO — Core0 access dio permission in world0.
  [27:26] CORE_0_PIF_PMS_CONSTRAIN_WORLD_0_AD — Core0 access ad permission in world0.
  [25:24] CORE_0_PIF_PMS_CONSTRAIN_WORLD_0_CACHE_CONFIG — Core0 access cache_config permission in world0.
  [23:22] CORE_0_PIF_PMS_CONSTRAIN_WORLD_0_DMA_COPY — Core0 access dma_copy permission in world0.
  [21:20] CORE_0_PIF_PMS_CONSTRAIN_WORLD_0_INTERRUPT — Core0 access interrupt permission in world0.
  [19:18] CORE_0_PIF_PMS_CONSTRAIN_WORLD_0_SENSITIVE — Core0 access sensitive permission in world0.
  [17:16] CORE_0_PIF_PMS_CONSTRAIN_WORLD_0_SYSTEM — Core0 access system permission in world0.
  [15:14] CORE_0_PIF_PMS_CONSTRAIN_WORLD_0_USB — Core0 access usb permission in world0.
  [13:12] CORE_0_PIF_PMS_CONSTRAIN_WORLD_0_BT_PWR — Core0 access bt_pwr permission in world0.
  [11:10] CORE_0_PIF_PMS_CONSTRAIN_WORLD_0_LCD_CAM — Core0 access lcd_cam permission in world0.
  [9:8] CORE_0_PIF_PMS_CONSTRAIN_WORLD_0_APB_ADC — Core0 access apb_adc permission in world0.
  [7:6] CORE_0_PIF_PMS_CONSTRAIN_WORLD_0_CRYPTO_DMA — Core0 access crypto_dma permission in world0.
  [5:4] CORE_0_PIF_PMS_CONSTRAIN_WORLD_0_CRYPTO_PERI — Core0 access crypto_peri permission in world0.
  [3:2] CORE_0_PIF_PMS_CONSTRAIN_WORLD_0_USB_WRAP — Core0 access usb_wrap permission in world0.
  [1:0] CORE_0_PIF_PMS_CONSTRAIN_WORLD_0_USB_DEVICE — Core0 access usb_device permission in world0.
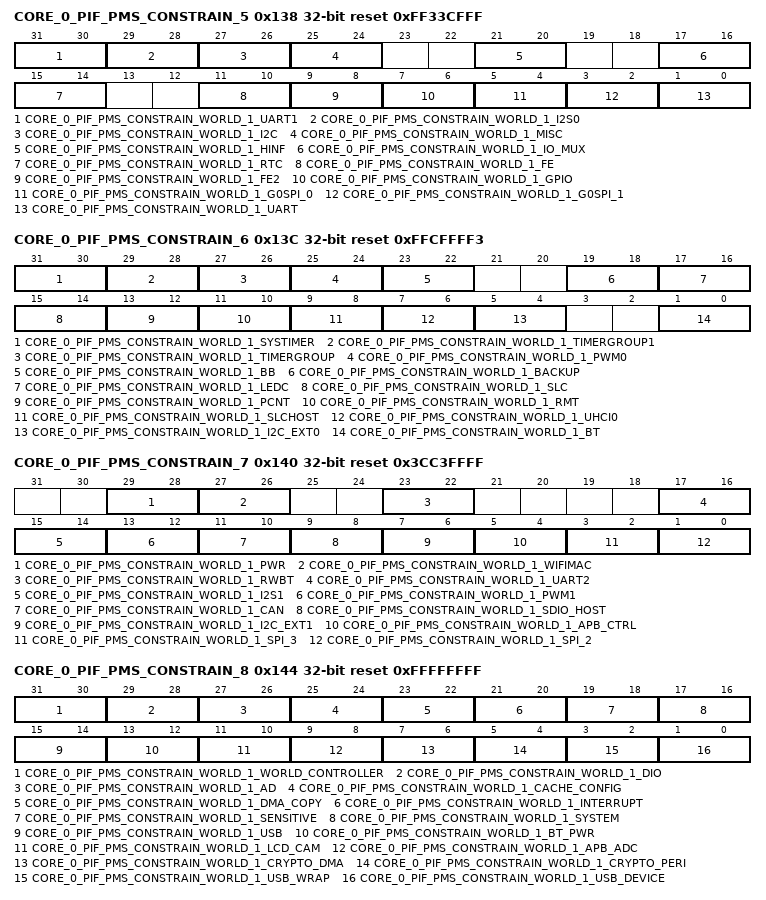
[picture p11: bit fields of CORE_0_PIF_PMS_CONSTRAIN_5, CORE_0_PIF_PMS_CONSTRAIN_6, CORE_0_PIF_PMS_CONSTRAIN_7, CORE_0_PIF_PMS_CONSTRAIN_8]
0x138 CORE_0_PIF_PMS_CONSTRAIN_5 reset 0xFF33CFFF — Core0 access peripherals permission configuration register 5.
  [31:30] CORE_0_PIF_PMS_CONSTRAIN_WORLD_1_UART1 — Core0 access uart1 permission in world1.
  [29:28] CORE_0_PIF_PMS_CONSTRAIN_WORLD_1_I2S0 — Core0 access i2s0 permission in world1.
  [27:26] CORE_0_PIF_PMS_CONSTRAIN_WORLD_1_I2C — Core0 access i2c permission in world1.
  [25:24] CORE_0_PIF_PMS_CONSTRAIN_WORLD_1_MISC — Core0 access misc permission in world1.
  [21:20] CORE_0_PIF_PMS_CONSTRAIN_WORLD_1_HINF — Core0 access hinf permission in world1.
  [17:16] CORE_0_PIF_PMS_CONSTRAIN_WORLD_1_IO_MUX — Core0 access io_mux permission in world1.
  [15:14] CORE_0_PIF_PMS_CONSTRAIN_WORLD_1_RTC — Core0 access rtc permission in world1.
  [11:10] CORE_0_PIF_PMS_CONSTRAIN_WORLD_1_FE — Core0 access fe permission in world1.
  [9:8] CORE_0_PIF_PMS_CONSTRAIN_WORLD_1_FE2 — Core0 access fe2 permission in world1.
  [7:6] CORE_0_PIF_PMS_CONSTRAIN_WORLD_1_GPIO — Core0 access gpio permission in world1.
  [5:4] CORE_0_PIF_PMS_CONSTRAIN_WORLD_1_G0SPI_0 — Core0 access g0spi_0 permission in world1.
  [3:2] CORE_0_PIF_PMS_CONSTRAIN_WORLD_1_G0SPI_1 — Core0 access g0spi_1 permission in world1.
  [1:0] CORE_0_PIF_PMS_CONSTRAIN_WORLD_1_UART — Core0 access uart permission in world1.
0x13C CORE_0_PIF_PMS_CONSTRAIN_6 reset 0xFFCFFFF3 — Core0 access peripherals permission configuration register 6.
  [31:30] CORE_0_PIF_PMS_CONSTRAIN_WORLD_1_SYSTIMER — Core0 access systimer permission in world1.
  [29:28] CORE_0_PIF_PMS_CONSTRAIN_WORLD_1_TIMERGROUP1 — Core0 access timergroup1 permission in world1.
  [27:26] CORE_0_PIF_PMS_CONSTRAIN_WORLD_1_TIMERGROUP — Core0 access timergroup permission in world1.
  [25:24] CORE_0_PIF_PMS_CONSTRAIN_WORLD_1_PWM0 — Core0 access pwm0 permission in world1.
  [23:22] CORE_0_PIF_PMS_CONSTRAIN_WORLD_1_BB — Core0 access bb permission in world1.
  [19:18] CORE_0_PIF_PMS_CONSTRAIN_WORLD_1_BACKUP — Core0 access backup permission in world1.
  [17:16] CORE_0_PIF_PMS_CONSTRAIN_WORLD_1_LEDC — Core0 access ledc permission in world1.
  [15:14] CORE_0_PIF_PMS_CONSTRAIN_WORLD_1_SLC — Core0 access slc permission in world1.
  [13:12] CORE_0_PIF_PMS_CONSTRAIN_WORLD_1_PCNT — Core0 access pcnt permission in world1.
  [11:10] CORE_0_PIF_PMS_CONSTRAIN_WORLD_1_RMT — Core0 access rmt permission in world1.
  [9:8] CORE_0_PIF_PMS_CONSTRAIN_WORLD_1_SLCHOST — Core0 access slchost permission in world1.
  [7:6] CORE_0_PIF_PMS_CONSTRAIN_WORLD_1_UHCI0 — Core0 access uhci0 permission in world1.
  [5:4] CORE_0_PIF_PMS_CONSTRAIN_WORLD_1_I2C_EXT0 — Core0 access i2c_ext0 permission in world1.
  [1:0] CORE_0_PIF_PMS_CONSTRAIN_WORLD_1_BT — Core0 access bt permission in world1.
0x140 CORE_0_PIF_PMS_CONSTRAIN_7 reset 0x3CC3FFFF — Core0 access peripherals permission configuration register 7.
  [29:28] CORE_0_PIF_PMS_CONSTRAIN_WORLD_1_PWR — Core0 access pwr permission in world1.
  [27:26] CORE_0_PIF_PMS_CONSTRAIN_WORLD_1_WIFIMAC — Core0 access wifimac permission in world1.
  [23:22] CORE_0_PIF_PMS_CONSTRAIN_WORLD_1_RWBT — Core0 access rwbt permission in world1.
  [17:16] CORE_0_PIF_PMS_CONSTRAIN_WORLD_1_UART2 — Core0 access uart2 permission in world1.
  [15:14] CORE_0_PIF_PMS_CONSTRAIN_WORLD_1_I2S1 — Core0 access i2s1 permission in world1.
  [13:12] CORE_0_PIF_PMS_CONSTRAIN_WORLD_1_PWM1 — Core0 access pwm1 permission in world1.
  [11:10] CORE_0_PIF_PMS_CONSTRAIN_WORLD_1_CAN — Core0 access can permission in world1.
  [9:8] CORE_0_PIF_PMS_CONSTRAIN_WORLD_1_SDIO_HOST — Core0 access sdio_host permission in world1.
  [7:6] CORE_0_PIF_PMS_CONSTRAIN_WORLD_1_I2C_EXT1 — Core0 access i2c_ext1 permission in world1.
  [5:4] CORE_0_PIF_PMS_CONSTRAIN_WORLD_1_APB_CTRL — Core0 access apb_ctrl permission in world1.
  [3:2] CORE_0_PIF_PMS_CONSTRAIN_WORLD_1_SPI_3 — Core0 access spi_3 permission in world1.
  [1:0] CORE_0_PIF_PMS_CONSTRAIN_WORLD_1_SPI_2 — Core0 access spi_2 permission in world1.
0x144 CORE_0_PIF_PMS_CONSTRAIN_8 reset 0xFFFFFFFF — Core0 access peripherals permission configuration register 8.
  [31:30] CORE_0_PIF_PMS_CONSTRAIN_WORLD_1_WORLD_CONTROLLER — Core0 access world_controller permission in world1.
  [29:28] CORE_0_PIF_PMS_CONSTRAIN_WORLD_1_DIO — Core0 access dio permission in world1.
  [27:26] CORE_0_PIF_PMS_CONSTRAIN_WORLD_1_AD — Core0 access ad permission in world1.
  [25:24] CORE_0_PIF_PMS_CONSTRAIN_WORLD_1_CACHE_CONFIG — Core0 access cache_config permission in world1.
  [23:22] CORE_0_PIF_PMS_CONSTRAIN_WORLD_1_DMA_COPY — Core0 access dma_copy permission in world1.
  [21:20] CORE_0_PIF_PMS_CONSTRAIN_WORLD_1_INTERRUPT — Core0 access interrupt permission in world1.
  [19:18] CORE_0_PIF_PMS_CONSTRAIN_WORLD_1_SENSITIVE — Core0 access sensitive permission in world1.
  [17:16] CORE_0_PIF_PMS_CONSTRAIN_WORLD_1_SYSTEM — Core0 access system permission in world1.
  [15:14] CORE_0_PIF_PMS_CONSTRAIN_WORLD_1_USB — Core0 access usb permission in world1.
  [13:12] CORE_0_PIF_PMS_CONSTRAIN_WORLD_1_BT_PWR — Core0 access bt_pwr permission in world1.
  [11:10] CORE_0_PIF_PMS_CONSTRAIN_WORLD_1_LCD_CAM — Core0 access lcd_cam permission in world1.
  [9:8] CORE_0_PIF_PMS_CONSTRAIN_WORLD_1_APB_ADC — Core0 access apb_adc permission in world1.
  [7:6] CORE_0_PIF_PMS_CONSTRAIN_WORLD_1_CRYPTO_DMA — Core0 access crypto_dma permission in world1.
  [5:4] CORE_0_PIF_PMS_CONSTRAIN_WORLD_1_CRYPTO_PERI — Core0 access crypto_peri permission in world1.
  [3:2] CORE_0_PIF_PMS_CONSTRAIN_WORLD_1_USB_WRAP — Core0 access usb_wrap permission in world1.
  [1:0] CORE_0_PIF_PMS_CONSTRAIN_WORLD_1_USB_DEVICE — Core0 access usb_device permission in world1.
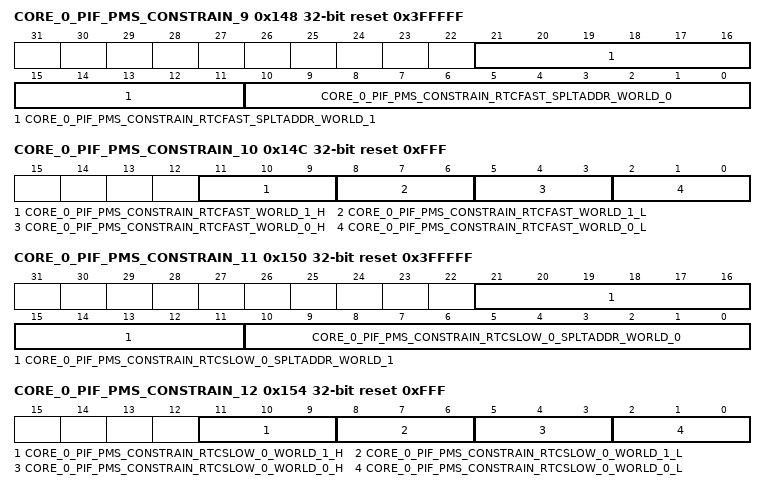
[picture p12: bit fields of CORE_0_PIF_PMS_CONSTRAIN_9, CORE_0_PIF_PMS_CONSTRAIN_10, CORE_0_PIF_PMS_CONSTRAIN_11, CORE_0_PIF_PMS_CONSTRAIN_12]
0x148 CORE_0_PIF_PMS_CONSTRAIN_9 reset 0x3FFFFF — Core0 access peripherals permission configuration register 9.
  [21:11] CORE_0_PIF_PMS_CONSTRAIN_RTCFAST_SPLTADDR_WORLD_1 — RTCFast memory split address in world 1 for core0.
  [10:0] CORE_0_PIF_PMS_CONSTRAIN_RTCFAST_SPLTADDR_WORLD_0 — RTCFast memory split address in world 0 for core0.
0x14C CORE_0_PIF_PMS_CONSTRAIN_10 reset 0xFFF — Core0 access peripherals permission configuration register 10.
  [11:9] CORE_0_PIF_PMS_CONSTRAIN_RTCFAST_WORLD_1_H — RTCFast memory high region permission in world 1 for core0.
  [8:6] CORE_0_PIF_PMS_CONSTRAIN_RTCFAST_WORLD_1_L — RTCFast memory low region permission in world 1 for core0.
  [5:3] CORE_0_PIF_PMS_CONSTRAIN_RTCFAST_WORLD_0_H — RTCFast memory high region permission in world 0 for core0.
  [2:0] CORE_0_PIF_PMS_CONSTRAIN_RTCFAST_WORLD_0_L — RTCFast memory low region permission in world 0 for core0.
0x150 CORE_0_PIF_PMS_CONSTRAIN_11 reset 0x3FFFFF — Core0 access peripherals permission configuration register 11.
  [21:11] CORE_0_PIF_PMS_CONSTRAIN_RTCSLOW_0_SPLTADDR_WORLD_1 — RTCSlow_0 memory split address in world 1 for core0.
  [10:0] CORE_0_PIF_PMS_CONSTRAIN_RTCSLOW_0_SPLTADDR_WORLD_0 — RTCSlow_0 memory split address in world 0 for core0.
0x154 CORE_0_PIF_PMS_CONSTRAIN_12 reset 0xFFF — Core0 access peripherals permission configuration register 12.
  [11:9] CORE_0_PIF_PMS_CONSTRAIN_RTCSLOW_0_WORLD_1_H — RTCSlow_0 memory high region permission in world 1 for core0.
  [8:6] CORE_0_PIF_PMS_CONSTRAIN_RTCSLOW_0_WORLD_1_L — RTCSlow_0 memory low region permission in world 1 for core0.
  [5:3] CORE_0_PIF_PMS_CONSTRAIN_RTCSLOW_0_WORLD_0_H — RTCSlow_0 memory high region permission in world 0 for core0.
  [2:0] CORE_0_PIF_PMS_CONSTRAIN_RTCSLOW_0_WORLD_0_L — RTCSlow_0 memory low region permission in world 0 for core0.
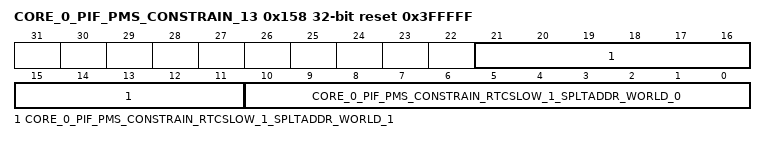
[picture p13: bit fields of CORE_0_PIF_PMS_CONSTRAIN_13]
0x158 CORE_0_PIF_PMS_CONSTRAIN_13 reset 0x3FFFFF — Core0 access peripherals permission configuration register 13.
  [21:11] CORE_0_PIF_PMS_CONSTRAIN_RTCSLOW_1_SPLTADDR_WORLD_1 — RTCSlow_1 memory split address in world 1 for core0.
  [10:0] CORE_0_PIF_PMS_CONSTRAIN_RTCSLOW_1_SPLTADDR_WORLD_0 — RTCSlow_1 memory split address in world 0 for core0.
